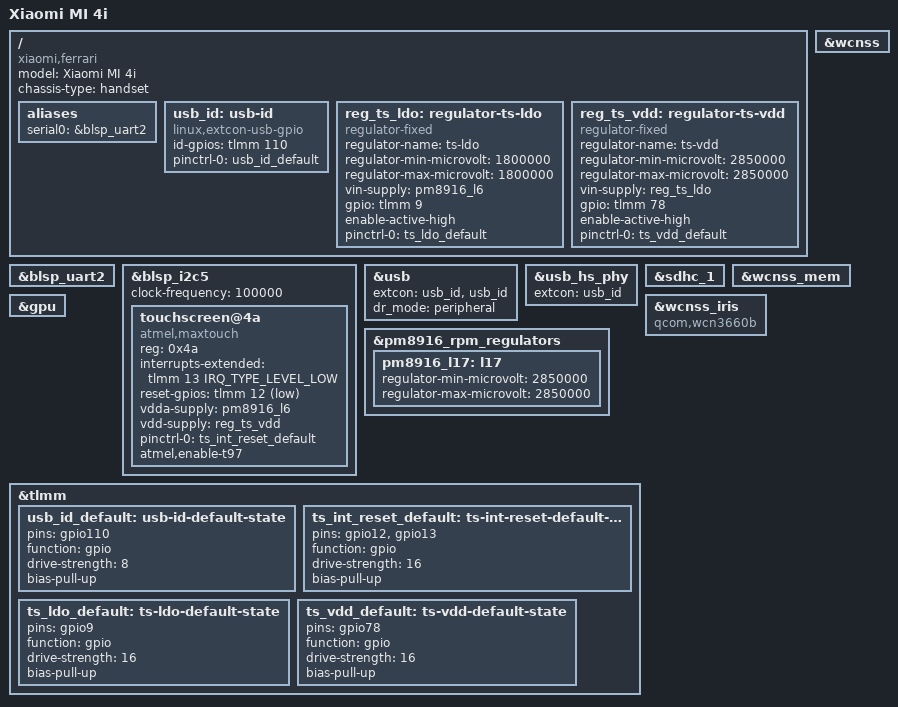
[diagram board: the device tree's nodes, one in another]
// SPDX-License-Identifier: GPL-2.0-only

/dts-v1/;

#include "msm8939-pm8916.dtsi"
#include <dt-bindings/gpio/gpio.h>
#include <dt-bindings/input/input.h>
#include <dt-bindings/interrupt-controller/irq.h>
#include <dt-bindings/leds/common.h>

/ {
	model = "Xiaomi MI 4i";
	compatible = "xiaomi,ferrari", "qcom,msm8939";
	chassis-type = "handset";

	aliases {
		serial0 = &blsp_uart2;
	};

	usb_id: usb-id {
		compatible = "linux,extcon-usb-gpio";
		id-gpios = <&tlmm 110 GPIO_ACTIVE_HIGH>;
		pinctrl-0 = <&usb_id_default>;
		pinctrl-names = "default";
	};

	reg_ts_ldo: regulator-ts-ldo {
		compatible = "regulator-fixed";
		regulator-name = "ts-ldo";
		regulator-min-microvolt = <1800000>;
		regulator-max-microvolt = <1800000>;
		vin-supply = <&pm8916_l6>;
		gpio = <&tlmm 9 GPIO_ACTIVE_HIGH>;
		enable-active-high;
		pinctrl-0 = <&ts_ldo_default>;
		pinctrl-names = "default";
	};

	reg_ts_vdd: regulator-ts-vdd {
		compatible = "regulator-fixed";
		regulator-name = "ts-vdd";
		regulator-min-microvolt = <2850000>;
		regulator-max-microvolt = <2850000>;
		vin-supply = <&reg_ts_ldo>;
		gpio = <&tlmm 78 GPIO_ACTIVE_HIGH>;
		enable-active-high;
		pinctrl-0 = <&ts_vdd_default>;
		pinctrl-names = "default";
	};

};

&blsp_uart2 {
	status = "okay";
};

&blsp_i2c5 {
	status = "okay";
	clock-frequency = <100000>;

	touchscreen@4a {
		compatible = "atmel,maxtouch";
		reg = <0x4a>;

		interrupts-extended = <&tlmm 13 IRQ_TYPE_LEVEL_LOW>;

		reset-gpios = <&tlmm 12 GPIO_ACTIVE_LOW>;

		vdda-supply = <&pm8916_l6>;
		vdd-supply = <&reg_ts_vdd>;

		pinctrl-0 = <&ts_int_reset_default>;
		pinctrl-names = "default";

		atmel,enable-t97;
	};
};

&usb {
	extcon = <&usb_id>, <&usb_id>;
	status = "okay";
	dr_mode = "peripheral";
};

&usb_hs_phy {
	extcon = <&usb_id>;
	status = "okay";
};

&sdhc_1 {
	status = "okay";
};

&wcnss {
	status = "okay";
};

&wcnss_mem {
	status = "okay";
};

&wcnss_iris {
	compatible = "qcom,wcn3660b";
};

&gpu {
	status = "okay";
};

&pm8916_rpm_regulators {
	pm8916_l17: l17 {
		regulator-min-microvolt = <2850000>;
		regulator-max-microvolt = <2850000>;
	};
};

&tlmm {
	usb_id_default: usb-id-default-state {
		pins = "gpio110";
		function = "gpio";
		drive-strength = <8>;
		bias-pull-up;
	};

	ts_int_reset_default: ts-int-reset-default-state {
		pins = "gpio12", "gpio13";
		function = "gpio";
		drive-strength = <16>;
		bias-pull-up;
	};

	ts_ldo_default: ts-ldo-default-state {
		pins = "gpio9";
		function = "gpio";
		drive-strength = <16>;
		bias-pull-up;
	};

	ts_vdd_default: ts-vdd-default-state {
		pins = "gpio78";
		function = "gpio";
		drive-strength = <16>;
		bias-pull-up;
	};

};
